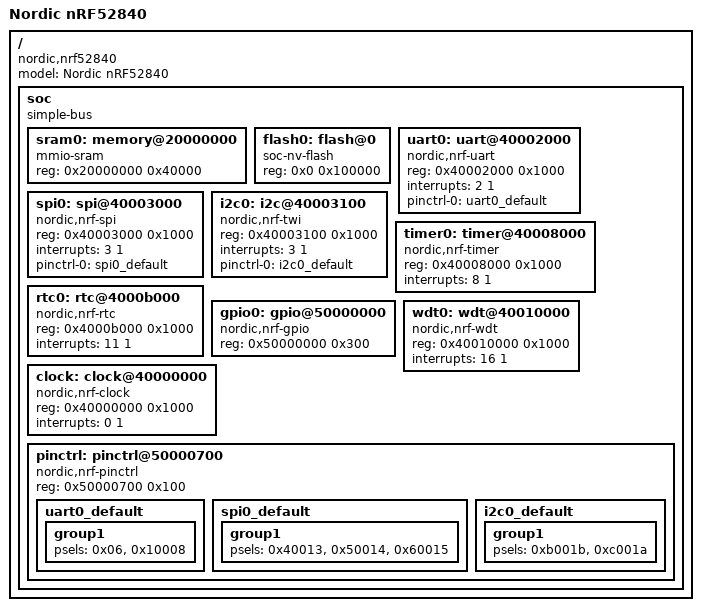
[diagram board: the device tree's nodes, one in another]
/*
 * Minimal Zephyr-style DTS fixture for the Nordic nRF52840.
 *
 * Snapshotted under tests/fixtures/zephyr-dts/ for the
 * `ingest-zephyr-dts-as-source` change.  Real Zephyr builds use
 * dts/arm/nordic/nrf52840.dtsi included into a board.dts; this
 * fixture is pre-flattened so the adapter can be exercised
 * without dragging in the full Zephyr binding tree.
 *
 * Carries enough peripherals to assert the adapter extracts the
 * canonical Nordic peripheral set (UART, SPI, TWI/I2C, TIMER,
 * RTC, GPIO).
 */
/dts-v1/;

/ {
    compatible = "nordic,nrf52840";
    model = "Nordic nRF52840";

    soc {
        compatible = "simple-bus";

        sram0: memory@20000000 {
            compatible = "mmio-sram";
            reg = <0x20000000 0x40000>;
        };

        flash0: flash@0 {
            compatible = "soc-nv-flash";
            reg = <0x0 0x100000>;
        };

        uart0: uart@40002000 {
            compatible = "nordic,nrf-uart";
            reg = <0x40002000 0x1000>;
            interrupts = <2 1>;
            status = "okay";
        };

        spi0: spi@40003000 {
            compatible = "nordic,nrf-spi";
            reg = <0x40003000 0x1000>;
            interrupts = <3 1>;
            status = "okay";
        };

        i2c0: i2c@40003100 {
            compatible = "nordic,nrf-twi";
            reg = <0x40003100 0x1000>;
            interrupts = <3 1>;
            status = "okay";
        };

        timer0: timer@40008000 {
            compatible = "nordic,nrf-timer";
            reg = <0x40008000 0x1000>;
            interrupts = <8 1>;
            status = "okay";
        };

        rtc0: rtc@4000b000 {
            compatible = "nordic,nrf-rtc";
            reg = <0x4000b000 0x1000>;
            interrupts = <11 1>;
            status = "okay";
        };

        gpio0: gpio@50000000 {
            compatible = "nordic,nrf-gpio";
            reg = <0x50000000 0x300>;
            status = "okay";
        };

        wdt0: wdt@40010000 {
            compatible = "nordic,nrf-wdt";
            reg = <0x40010000 0x1000>;
            interrupts = <16 1>;
            status = "okay";
        };

        clock: clock@40000000 {
            compatible = "nordic,nrf-clock";
            reg = <0x40000000 0x1000>;
            interrupts = <0 1>;
            status = "okay";
        };

        /*
         * Pinctrl groups for Zephyr peripherals.
         *
         * `psels` cells are NRF_PSEL macro-expanded values:
         *   ((NRF_FUN_<fun> << 16) | (port << 5) | pin)
         *
         * Examples in this fixture:
         *   UART0 TX on P0_06: NRF_FUN_UART_TX(0) << 16 | 0<<5 | 6 = 0x06
         *   UART0 RX on P0_08: NRF_FUN_UART_RX(1) << 16 | 0<<5 | 8 = 0x10008
         *   SPI0 SCK on P0_19: NRF_FUN_SPIM_SCK(4) << 16 | 0<<5 | 19 = 0x40013
         *   SPI0 MOSI on P0_20: 5 << 16 | 0<<5 | 20 = 0x50014
         *   SPI0 MISO on P0_21: 6 << 16 | 0<<5 | 21 = 0x60015
         *   I2C0 SCL on P0_27: 11 << 16 | 0<<5 | 27 = 0xb001b
         *   I2C0 SDA on P0_26: 12 << 16 | 0<<5 | 26 = 0xc001a
         */
        pinctrl: pinctrl@50000700 {
            compatible = "nordic,nrf-pinctrl";
            reg = <0x50000700 0x100>;

            uart0_default: uart0_default {
                group1 {
                    psels = <0x06>, <0x10008>;
                };
            };

            spi0_default: spi0_default {
                group1 {
                    psels = <0x40013>, <0x50014>, <0x60015>;
                };
            };

            i2c0_default: i2c0_default {
                group1 {
                    psels = <0xb001b>, <0xc001a>;
                };
            };
        };
    };
};

/* Phandle wiring: associate each peripheral with its pinctrl group. */
&uart0 {
    pinctrl-0 = <&uart0_default>;
    pinctrl-names = "default";
};

&spi0 {
    pinctrl-0 = <&spi0_default>;
    pinctrl-names = "default";
};

&i2c0 {
    pinctrl-0 = <&i2c0_default>;
    pinctrl-names = "default";
};
